VERSION "f32"

NS_ :

BS_:

BU_: C70 VC MCU BMS CHG DASH PBX

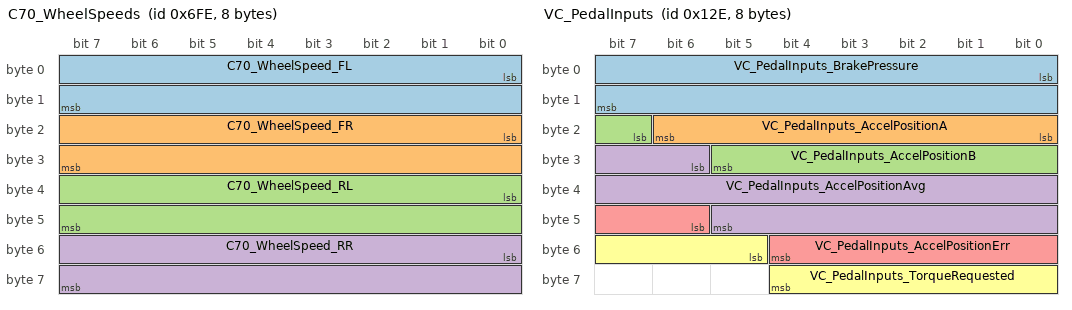
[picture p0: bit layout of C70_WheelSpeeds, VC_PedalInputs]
BO_ 1790 C70_WheelSpeeds: 8 C70
 SG_ C70_WheelSpeed_FL : 0|16@1- (1,0) [0|65536] ""  C70
 SG_ C70_WheelSpeed_FR : 16|16@1- (1,0) [0|65536] ""  C70
 SG_ C70_WheelSpeed_RL : 32|16@1- (1,0) [0|65536] ""  C70
 SG_ C70_WheelSpeed_RR : 48|16@1- (1,0) [0|65536] ""  C70

BO_ 1791 C70_BrakePressures: 8 C70
 SG_ C70_BrakePressureFront : 0|16@1- (0.2,1250) [0|2500] "psi" Vector__XXX
 SG_ C70_BrakePressureRear : 16|16@1- (0.2,1250) [0|2500] "psi" Vector__XXX

BO_ 301 VC_Status: 8 VC
 SG_ VC_Status_VehicleState : 0|4@1+ (1,0) [0|15] ""  DASH
 SG_ VC_Status_MC_State : 4|4@1+ (1,0) [0|15] ""  DASH

BO_ 302 VC_PedalInputs: 8 VC
 SG_ VC_PedalInputs_BrakePressure : 0|16@1+ (0.1,0) [0|3000] "psi" Vector__XXX
 SG_ VC_PedalInputs_AccelPositionA : 16|7@1+ (1,0) [0|100] "%" Vector__XXX
 SG_ VC_PedalInputs_AccelPositionB : 23|7@1+ (1,0) [0|100] "%" Vector__XXX
 SG_ VC_PedalInputs_AccelPositionAvg : 30|16@1+ (0.1,0) [0|100] "%" Vector__XXX
 SG_ VC_PedalInputs_AccelPositionErr : 46|7@1+ (1,0) [0|100] "%" Vector__XXX
 SG_ VC_PedalInputs_TorqueRequested : 53|8@1+ (1,0) [0|254] "Nm" Vector__XXX

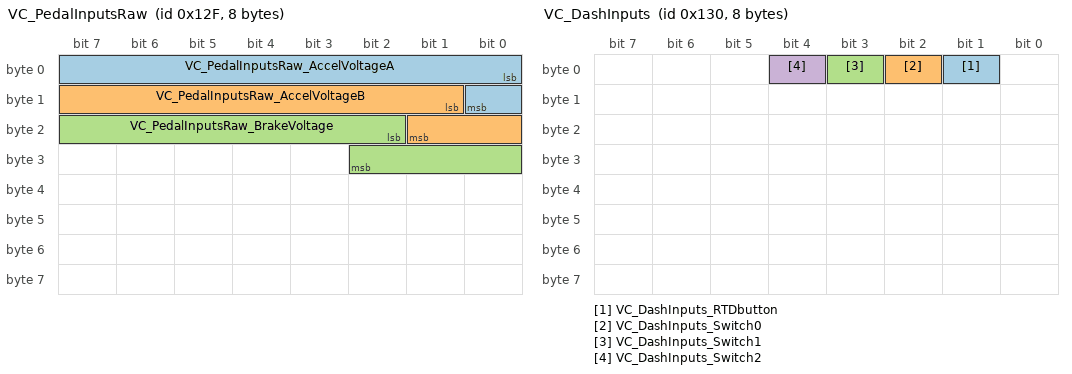
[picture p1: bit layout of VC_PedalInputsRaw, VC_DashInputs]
BO_ 303 VC_PedalInputsRaw: 8 VC
 SG_ VC_PedalInputsRaw_AccelVoltageA : 0|9@1+ (0.01,0) [0|5] "V" Vector__XXX
 SG_ VC_PedalInputsRaw_AccelVoltageB : 9|9@1+ (0.01,0) [0|5] "V" Vector__XXX
 SG_ VC_PedalInputsRaw_BrakeVoltage : 18|9@1+ (0.01,0) [0|5] "V" Vector__XXX

BO_ 304 VC_DashInputs: 8 VC
 SG_ VC_DashInputs_RTDbutton : 1|1@1+ (1,0) [0|1] "" Vector__XXX
 SG_ VC_DashInputs_Switch0 : 2|1@1+ (1,0) [0|1] "" Vector__XXX
 SG_ VC_DashInputs_Switch1 : 3|1@1+ (1,0) [0|1] "" Vector__XXX
 SG_ VC_DashInputs_Switch2 : 4|1@1+ (1,0) [0|1] "" Vector__XXX

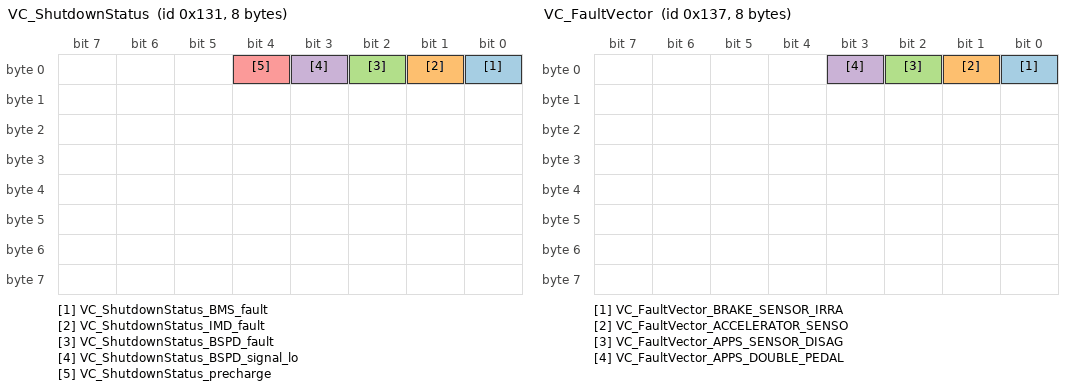
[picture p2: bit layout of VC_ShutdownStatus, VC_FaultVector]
BO_ 305 VC_ShutdownStatus: 8 VC
 SG_ VC_ShutdownStatus_BMS_fault : 0|1@1+ (1,0) [0|1] "" Vector__XXX
 SG_ VC_ShutdownStatus_IMD_fault : 1|1@1+ (1,0) [0|1] "" Vector__XXX
 SG_ VC_ShutdownStatus_BSPD_fault : 2|1@1+ (1,0) [0|1] "" Vector__XXX
 SG_ VC_ShutdownStatus_BSPD_signal_lo : 3|1@1+ (1,0) [0|1] "" Vector__XXX
 SG_ VC_ShutdownStatus_precharge : 4|1@1+ (1,0) [0|1] "" Vector__XXX

BO_ 311 VC_FaultVector: 8 VC
 SG_ VC_FaultVector_BRAKE_SENSOR_IRRA : 0|1@1+ (1,0) [0|1] ""  DASH
 SG_ VC_FaultVector_ACCELERATOR_SENSO : 1|1@1+ (1,0) [0|1] ""  DASH
 SG_ VC_FaultVector_APPS_SENSOR_DISAG : 2|1@1+ (1,0) [0|1] ""  DASH
 SG_ VC_FaultVector_APPS_DOUBLE_PEDAL : 3|1@1+ (1,0) [0|1] ""  DASH

BO_ 315 VC_HardFaultIndicator: 8 VC
 SG_ VC_HardFaultIndicator_task : 0|4@1+ (1,0) [0|15] ""  DASH

BO_ 316 VC_RTDSRequest: 8 VC
 SG_ VC_RequestRTDS : 0|1@1+ (1,0) [0|1] "" Vector__XXX

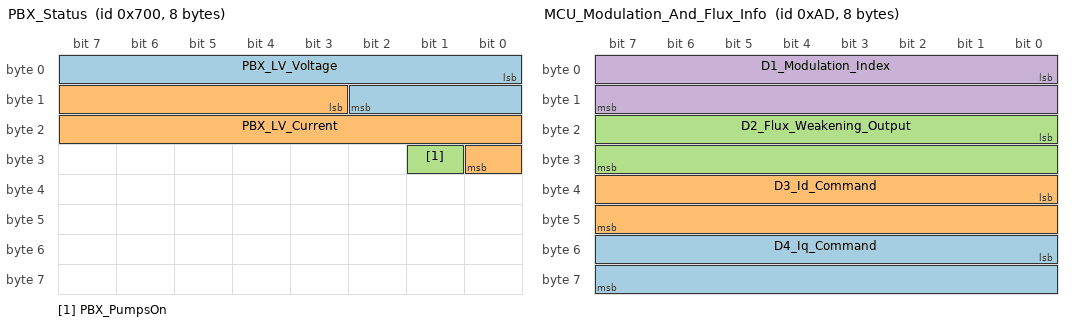
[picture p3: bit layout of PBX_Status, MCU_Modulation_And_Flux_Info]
BO_ 1792 PBX_Status: 8 PBX
 SG_ PBX_LV_Voltage : 0|11@1+ (0.01,0) [0|20] "V" Vector__XXX
 SG_ PBX_LV_Current : 11|14@1+ (0.01,0) [0|100] "A" Vector__XXX
 SG_ PBX_PumpsOn : 25|1@1+ (1,0) [0|1] ""  VC

BO_ 173 MCU_Modulation_And_Flux_Info: 8 MCU
 SG_ D4_Iq_Command : 48|16@1- (0.1,0) [-3276.8|3276.7] "A" Vector__XXX
 SG_ D3_Id_Command : 32|16@1- (0.1,0) [-3276.8|3276.7] "A" Vector__XXX
 SG_ D2_Flux_Weakening_Output : 16|16@1- (0.1,0) [-3276.8|3276.7] "A" Vector__XXX
 SG_ D1_Modulation_Index : 0|16@1- (0.0001,0) [-3.2768|3.2767] "" Vector__XXX

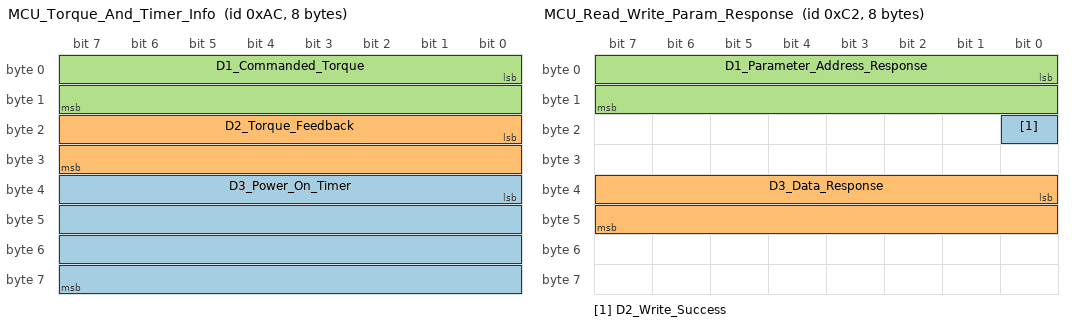
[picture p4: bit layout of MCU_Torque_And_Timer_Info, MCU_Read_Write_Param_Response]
BO_ 172 MCU_Torque_And_Timer_Info: 8 MCU
 SG_ D3_Power_On_Timer : 32|32@1+ (0.003,0) [0|12884800] "Sec" Vector__XXX
 SG_ D2_Torque_Feedback : 16|16@1- (0.1,0) [-3276.8|3276.7] "Nm" Vector__XXX
 SG_ D1_Commanded_Torque : 0|16@1- (0.1,0) [-3276.8|3276.7] "Nm" Vector__XXX

BO_ 194 MCU_Read_Write_Param_Response: 8 MCU
 SG_ D2_Write_Success : 16|1@1+ (1,0) [0|1] "" Vector__XXX
 SG_ D3_Data_Response : 32|16@1- (1,0) [-32768|32767] "" Vector__XXX
 SG_ D1_Parameter_Address_Response : 0|16@1+ (1,0) [0|65535] "" Vector__XXX

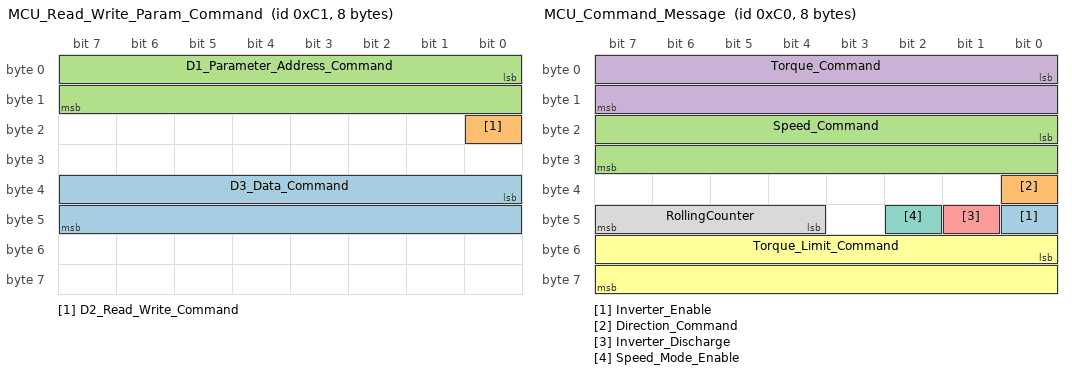
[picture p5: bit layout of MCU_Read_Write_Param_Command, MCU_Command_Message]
BO_ 193 MCU_Read_Write_Param_Command: 8 VC
 SG_ D3_Data_Command : 32|16@1- (1,0) [-32768|32767] ""  MCU
 SG_ D2_Read_Write_Command : 16|1@1+ (1,0) [0|1] ""  MCU
 SG_ D1_Parameter_Address_Command : 0|16@1+ (1,0) [0|65535] ""  MCU

BO_ 192 MCU_Command_Message: 8 VC
 SG_ Inverter_Enable : 40|1@1+ (1,0) [0|1] "Bit"  MCU
 SG_ Direction_Command : 32|1@1+ (1,0) [0|1] "Bit"  MCU
 SG_ Speed_Command : 16|16@1- (1,0) [-32768|32767] "rpm"  MCU
 SG_ Torque_Command : 0|16@1- (0.1,0) [-3276.8|3276.7] "Nm"  MCU
 SG_ Inverter_Discharge : 41|1@1+ (1,0) [0|1] "Bit"  MCU
 SG_ Torque_Limit_Command : 48|16@1- (0.1,0) [-3276.8|3276.7] "Nm"  MCU
 SG_ Speed_Mode_Enable : 42|1@1+ (1,0) [0|1] "Bit"  MCU
 SG_ RollingCounter : 44|4@1+ (1,0) [0|15] "Bits"  MCU

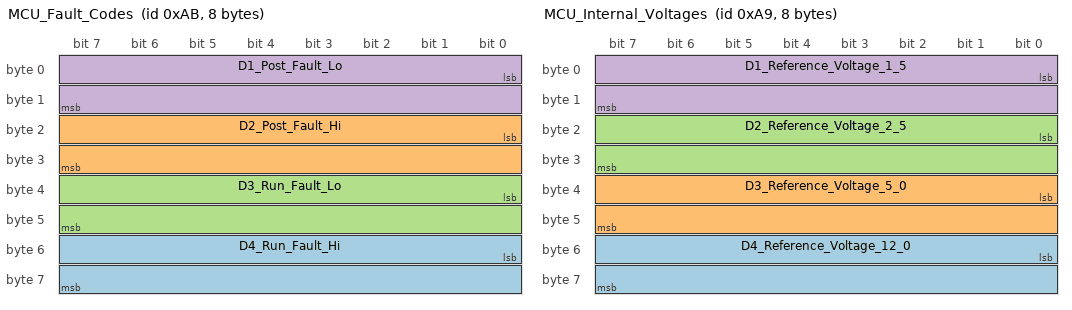
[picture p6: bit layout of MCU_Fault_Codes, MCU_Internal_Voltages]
BO_ 171 MCU_Fault_Codes: 8 MCU
 SG_ D4_Run_Fault_Hi : 48|16@1+ (1,0) [0|65535] "" Vector__XXX
 SG_ D2_Post_Fault_Hi : 16|16@1+ (1,0) [0|65535] "" Vector__XXX
 SG_ D3_Run_Fault_Lo : 32|16@1+ (1,0) [0|65535] "" Vector__XXX
 SG_ D1_Post_Fault_Lo : 0|16@1+ (1,0) [0|65535] "" Vector__XXX

BO_ 170 MCU_Internal_States: 8 MCU
 SG_ D7_Direction_Command : 56|1@1+ (1,0) [0|1] "" Vector__XXX
 SG_ D6_Inverter_Enable_State : 48|1@1+ (1,0) [0|1] "" Vector__XXX
 SG_ D3_Relay_3_Status : 26|1@1+ (1,0) [0|1] "" Vector__XXX
 SG_ D3_Relay_4_Status : 27|1@1+ (1,0) [0|1] "" Vector__XXX
 SG_ D3_Relay_2_Status : 25|1@1+ (1,0) [0|1] "" Vector__XXX
 SG_ D4_Inverter_Run_Mode : 32|1@1+ (1,0) [0|1] "" Vector__XXX
 SG_ D5_Inverter_Command_Mode : 40|1@1+ (1,0) [0|1] "" Vector__XXX
 SG_ D3_Relay_1_Status : 24|1@1+ (1,0) [0|1] "" Vector__XXX
 SG_ D2_Inverter_State : 16|8@1+ (1,0) [0|255] "" Vector__XXX
 SG_ D1_VSM_State : 0|8@1+ (1,0) [0|15] "" Vector__XXX
 SG_ D6_Inverter_Enable_Lockout : 55|1@1+ (1,0) [0|1] "" Vector__XXX
 SG_ D4_Inverter_Discharge_State : 37|3@1+ (1,0) [0|7] "" Vector__XXX
 SG_ D3_Relay_5_Status : 28|1@1+ (1,0) [0|1] "" Vector__XXX
 SG_ D3_Relay_6_Status : 29|1@1+ (1,0) [0|1] "" Vector__XXX
 SG_ D7_BMS_Active : 57|1@1+ (1,0) [0|1] "" Vector__XXX
 SG_ D7_BMS_Torque_Limiting : 58|1@1+ (1,0) [0|1] "" Vector__XXX
 SG_ D7_Max_Speed_Limiting : 59|1@1+ (1,0) [0|1] "" Vector__XXX
 SG_ D7_Low_Speed_Limiting : 61|1@1+ (1,0) [0|1] "" Vector__XXX
 SG_ D5_Rolling_Counter : 44|4@1+ (1,0) [0|15] "" Vector__XXX
 SG_ D1_PWM_Frequency : 8|8@1+ (1,0) [0|255] "kHz" Vector__XXX
 SG_ D6_Start_Mode_Active : 54|1@1+ (1,0) [0|1] "" Vector__XXX

BO_ 169 MCU_Internal_Voltages: 8 MCU
 SG_ D4_Reference_Voltage_12_0 : 48|16@1- (0.01,0) [-327.68|327.67] "V" Vector__XXX
 SG_ D3_Reference_Voltage_5_0 : 32|16@1- (0.01,0) [-327.68|327.67] "V" Vector__XXX
 SG_ D2_Reference_Voltage_2_5 : 16|16@1- (0.01,0) [-327.68|327.67] "V" Vector__XXX
 SG_ D1_Reference_Voltage_1_5 : 0|16@1- (0.01,0) [-327.68|327.67] "V" Vector__XXX

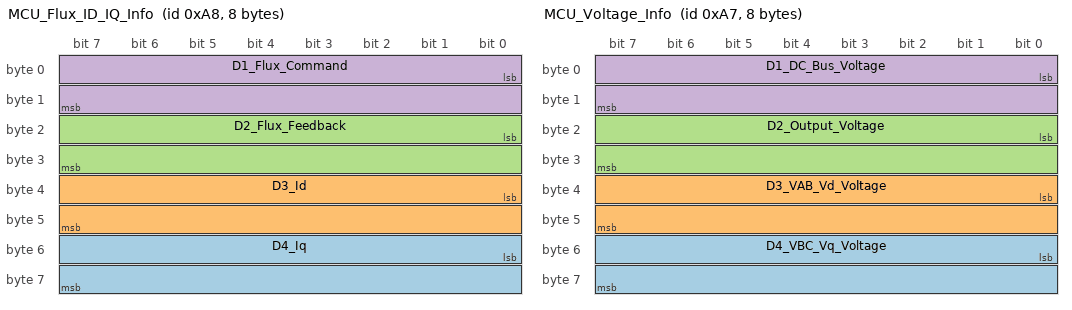
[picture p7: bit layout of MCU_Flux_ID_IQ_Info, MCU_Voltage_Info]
BO_ 168 MCU_Flux_ID_IQ_Info: 8 MCU
 SG_ D4_Iq : 48|16@1- (0.1,0) [-3276.8|3276.7] "A" Vector__XXX
 SG_ D3_Id : 32|16@1- (0.1,0) [-3276.8|3276.7] "A" Vector__XXX
 SG_ D2_Flux_Feedback : 16|16@1- (0.001,0) [-32.768|32.767] "Wb" Vector__XXX
 SG_ D1_Flux_Command : 0|16@1- (0.001,0) [-32.768|32.767] "Wb" Vector__XXX

BO_ 167 MCU_Voltage_Info: 8 MCU
 SG_ D4_VBC_Vq_Voltage : 48|16@1- (0.1,0) [-3276.8|3276.7] "V" Vector__XXX
 SG_ D3_VAB_Vd_Voltage : 32|16@1- (0.1,0) [-3276.8|3276.7] "V" Vector__XXX
 SG_ D2_Output_Voltage : 16|16@1- (0.1,0) [-3276.8|3276.7] "V" Vector__XXX
 SG_ D1_DC_Bus_Voltage : 0|16@1- (0.1,0) [-3276.8|3276.7] "V" Vector__XXX

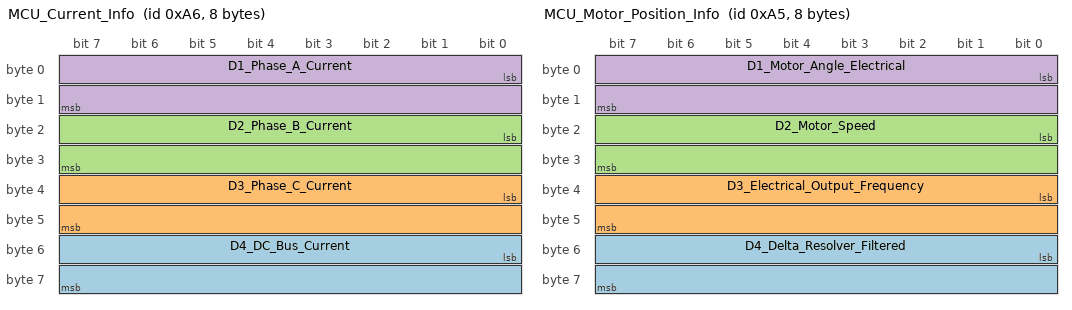
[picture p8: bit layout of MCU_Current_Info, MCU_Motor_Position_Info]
BO_ 166 MCU_Current_Info: 8 MCU
 SG_ D4_DC_Bus_Current : 48|16@1- (0.1,0) [-3276.8|3276.7] "A" Vector__XXX
 SG_ D3_Phase_C_Current : 32|16@1- (0.1,0) [-3276.8|3276.7] "A" Vector__XXX
 SG_ D2_Phase_B_Current : 16|16@1- (0.1,0) [-3276.8|3276.7] "A" Vector__XXX
 SG_ D1_Phase_A_Current : 0|16@1- (0.1,0) [-3276.8|3276.7] "A" Vector__XXX

BO_ 165 MCU_Motor_Position_Info: 8 MCU
 SG_ D4_Delta_Resolver_Filtered : 48|16@1- (0.1,0) [-3276.8|3276.7] "deg" Vector__XXX
 SG_ D3_Electrical_Output_Frequency : 32|16@1- (0.1,0) [-3276.8|3276.7] "hz" Vector__XXX
 SG_ D2_Motor_Speed : 16|16@1- (1,0) [-32768|32767] "rpm"  DASH
 SG_ D1_Motor_Angle_Electrical : 0|16@1+ (0.1,0) [0|6553.5] "deg" Vector__XXX

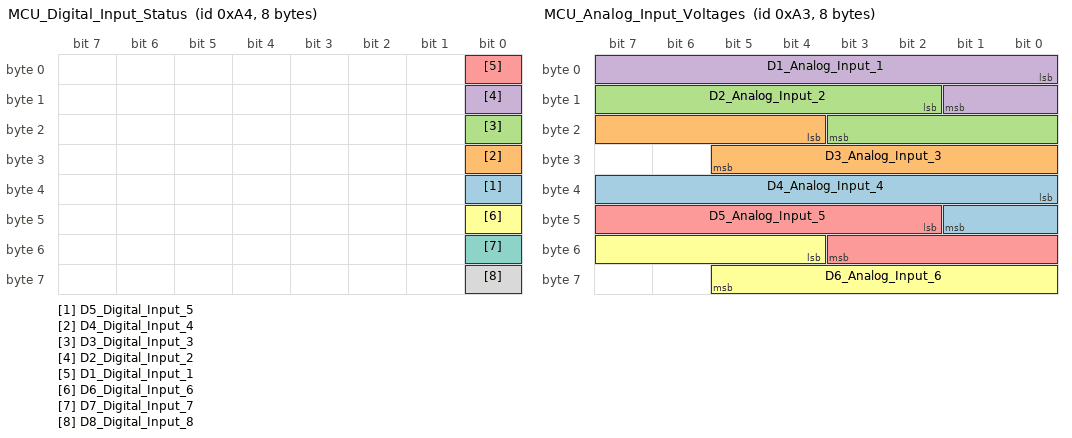
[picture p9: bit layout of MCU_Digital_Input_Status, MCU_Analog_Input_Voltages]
BO_ 164 MCU_Digital_Input_Status: 8 MCU
 SG_ D5_Digital_Input_5 : 32|1@1+ (1,0) [0|1] "boolean" Vector__XXX
 SG_ D4_Digital_Input_4 : 24|1@1+ (1,0) [0|1] "boolean" Vector__XXX
 SG_ D3_Digital_Input_3 : 16|1@1+ (1,0) [0|1] "boolean" Vector__XXX
 SG_ D2_Digital_Input_2 : 8|1@1+ (1,0) [0|1] "boolean" Vector__XXX
 SG_ D1_Digital_Input_1 : 0|1@1+ (1,0) [0|1] "boolean" Vector__XXX
 SG_ D6_Digital_Input_6 : 40|1@1+ (1,0) [0|1] "boolean" Vector__XXX
 SG_ D7_Digital_Input_7 : 48|1@1+ (1,0) [0|1] "boolean" Vector__XXX
 SG_ D8_Digital_Input_8 : 56|1@1+ (1,0) [0|1] "boolean" Vector__XXX

BO_ 163 MCU_Analog_Input_Voltages: 8 MCU
 SG_ D4_Analog_Input_4 : 32|10@1+ (0.01,0) [0|10.23] "V" Vector__XXX
 SG_ D3_Analog_Input_3 : 20|10@1+ (0.01,0) [0|10.23] "V" Vector__XXX
 SG_ D2_Analog_Input_2 : 10|10@1+ (0.01,0) [0|10.23] "V" Vector__XXX
 SG_ D1_Analog_Input_1 : 0|10@1+ (0.01,0) [0|10.23] "V" Vector__XXX
 SG_ D5_Analog_Input_5 : 42|10@1+ (0.01,0) [0|10.23] "V" Vector__XXX
 SG_ D6_Analog_Input_6 : 52|10@1+ (0.01,0) [0|10.23] "V" Vector__XXX

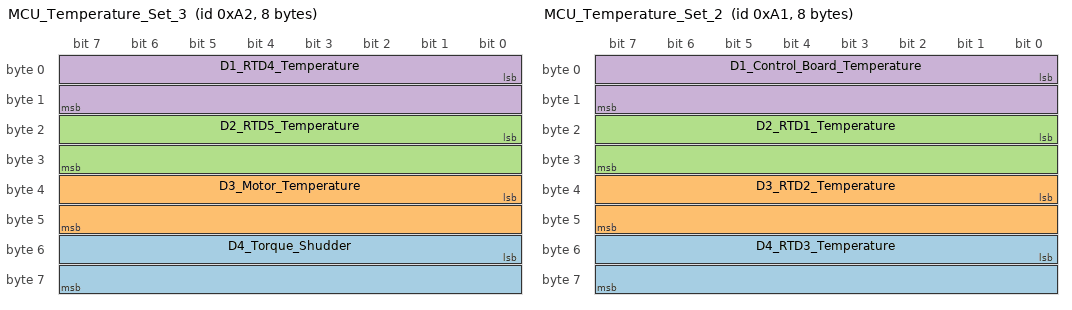
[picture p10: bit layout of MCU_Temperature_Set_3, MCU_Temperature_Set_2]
BO_ 162 MCU_Temperature_Set_3: 8 MCU
 SG_ D4_Torque_Shudder : 48|16@1- (0.1,0) [-3276.8|3276.7] "Nm" Vector__XXX
 SG_ D3_Motor_Temperature : 32|16@1- (0.1,0) [-3276.8|3276.7] "degC" Vector__XXX
 SG_ D2_RTD5_Temperature : 16|16@1- (0.1,0) [-3276.8|3276.7] "degC" Vector__XXX
 SG_ D1_RTD4_Temperature : 0|16@1- (0.1,0) [-3276.8|3276.7] "degC" Vector__XXX

BO_ 161 MCU_Temperature_Set_2: 8 MCU
 SG_ D4_RTD3_Temperature : 48|16@1- (0.1,0) [-3276.8|3276.7] "degC" Vector__XXX
 SG_ D3_RTD2_Temperature : 32|16@1- (0.1,0) [-3276.8|3276.7] "degC" Vector__XXX
 SG_ D2_RTD1_Temperature : 16|16@1- (0.1,0) [-3276.8|3276.7] "degC" Vector__XXX
 SG_ D1_Control_Board_Temperature : 0|16@1- (0.1,0) [-3276.8|3276.7] "degC" Vector__XXX

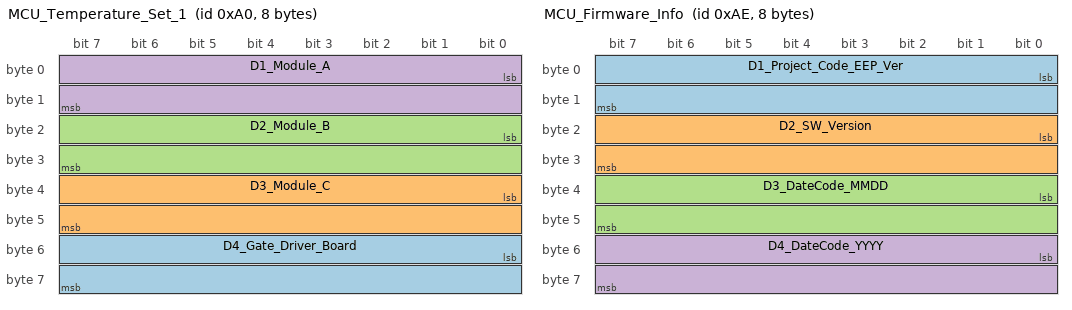
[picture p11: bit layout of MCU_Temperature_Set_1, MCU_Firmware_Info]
BO_ 160 MCU_Temperature_Set_1: 8 MCU
 SG_ D4_Gate_Driver_Board : 48|16@1- (0.1,0) [-3276.8|3276.7] "degC" Vector__XXX
 SG_ D3_Module_C : 32|16@1- (0.1,0) [-3276.8|3276.7] "degC" Vector__XXX
 SG_ D2_Module_B : 16|16@1- (0.1,0) [-3276.8|3276.7] "degC" Vector__XXX
 SG_ D1_Module_A : 0|16@1- (0.1,0) [-3276.8|3276.7] "degC" Vector__XXX

BO_ 174 MCU_Firmware_Info: 8 MCU
 SG_ D1_Project_Code_EEP_Ver : 0|16@1+ (1,0) [0|65535] "" Vector__XXX
 SG_ D2_SW_Version : 16|16@1+ (1,0) [0|65535] "" Vector__XXX
 SG_ D3_DateCode_MMDD : 32|16@1+ (1,0) [0|65535] "" Vector__XXX
 SG_ D4_DateCode_YYYY : 48|16@1+ (1,0) [0|65535] "" Vector__XXX

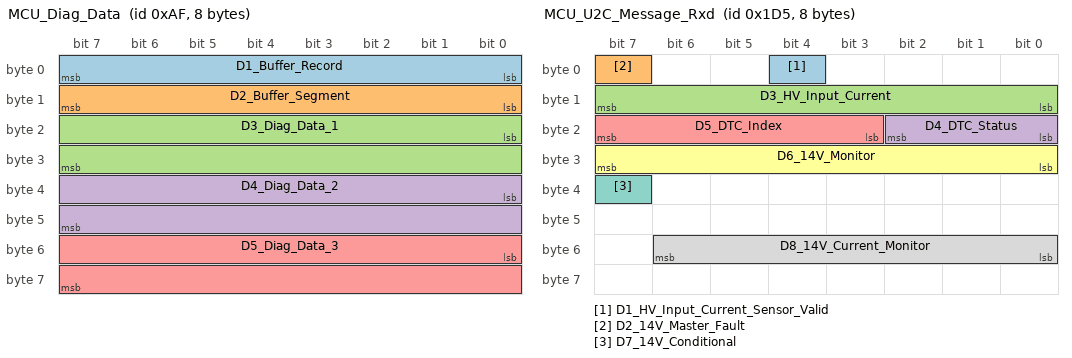
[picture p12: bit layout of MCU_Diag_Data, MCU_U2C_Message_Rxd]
BO_ 175 MCU_Diag_Data: 8 MCU
 SG_ D1_Buffer_Record : 0|8@1+ (1,0) [0|255] "" Vector__XXX
 SG_ D2_Buffer_Segment : 8|8@1+ (1,0) [0|5] "" Vector__XXX
 SG_ D3_Diag_Data_1 : 16|16@1- (1,0) [-32768|32767] "" Vector__XXX
 SG_ D4_Diag_Data_2 : 32|16@1- (1,0) [-32768|32767] "" Vector__XXX
 SG_ D5_Diag_Data_3 : 48|16@1- (1,0) [-32768|32767] "" Vector__XXX

BO_ 471 MCU_U2C_Command_Txd: 8 MCU
 SG_ D1_ID_Byte : 0|8@1+ (1,0) [0|255] "" Vector__XXX
 SG_ D2_Setpoint_Calc : 8|8@1+ (1,0) [0|255] "" Vector__XXX

BO_ 469 MCU_U2C_Message_Rxd: 8 MCU
 SG_ D1_HV_Input_Current_Sensor_Valid : 4|1@1+ (1,0) [0|1] "" Vector__XXX
 SG_ D2_14V_Master_Fault : 7|1@1+ (1,0) [0|1] "" Vector__XXX
 SG_ D3_HV_Input_Current : 8|8@1+ (1,0) [0|255] "" Vector__XXX
 SG_ D4_DTC_Status : 16|3@1+ (1,0) [0|7] "" Vector__XXX
 SG_ D5_DTC_Index : 19|5@1+ (1,0) [0|31] "" Vector__XXX
 SG_ D6_14V_Monitor : 24|8@1+ (1,0) [0|255] "" Vector__XXX
 SG_ D7_14V_Conditional : 39|1@1+ (1,0) [0|1] "" Vector__XXX
 SG_ D8_14V_Current_Monitor : 48|7@1+ (1,0) [0|127] "" Vector__XXX

BO_ 514 BMS_Current_Limit: 8 BMS
 SG_ D1_Max_Discharge_Current : 0|16@1+ (1,0) [0|1000] "A" Vector__XXX
 SG_ D2_Max_Charge_Current : 16|16@1+ (1,0) [0|1000] "A" Vector__XXX

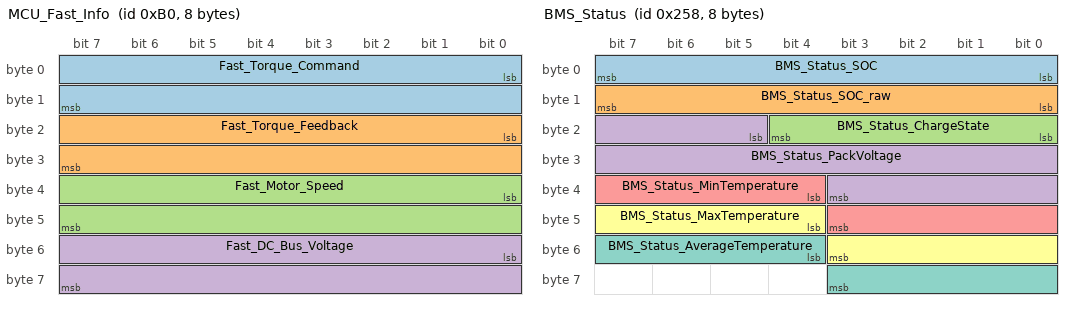
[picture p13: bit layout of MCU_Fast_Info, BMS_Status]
BO_ 176 MCU_Fast_Info: 8 MCU
 SG_ Fast_Torque_Command : 0|16@1- (0.1,0) [-3276.8|3276.7] "Nm" Vector__XXX
 SG_ Fast_Torque_Feedback : 16|16@1- (0.1,0) [-3276.8|3276.7] "Nm" Vector__XXX
 SG_ Fast_Motor_Speed : 32|16@1- (1,0) [-32768|32767] "rpm" Vector__XXX
 SG_ Fast_DC_Bus_Voltage : 48|16@1- (0.1,0) [-3276.8|3276.7] "V" Vector__XXX

BO_ 600 BMS_Status: 8 BMS
 SG_ BMS_Status_SOC : 0|8@1+ (1,0) [0|100] "%"  DASH
 SG_ BMS_Status_SOC_raw : 8|8@1+ (1,0) [0|100] "%" Vector__XXX
 SG_ BMS_Status_ChargeState : 16|5@1+ (1,0) [0|4] "" Vector__XXX
 SG_ BMS_Status_PackVoltage : 21|15@1+ (0.1,0) [0|400] "V"  DASH
 SG_ BMS_Status_MinTemperature : 36|8@1- (1,0) [-128|127] "C" Vector__XXX
 SG_ BMS_Status_MaxTemperature : 44|8@1- (1,0) [-128|127] "C" Vector__XXX
 SG_ BMS_Status_AverageTemperature : 52|8@1- (1,0) [-128|127] "C" Vector__XXX

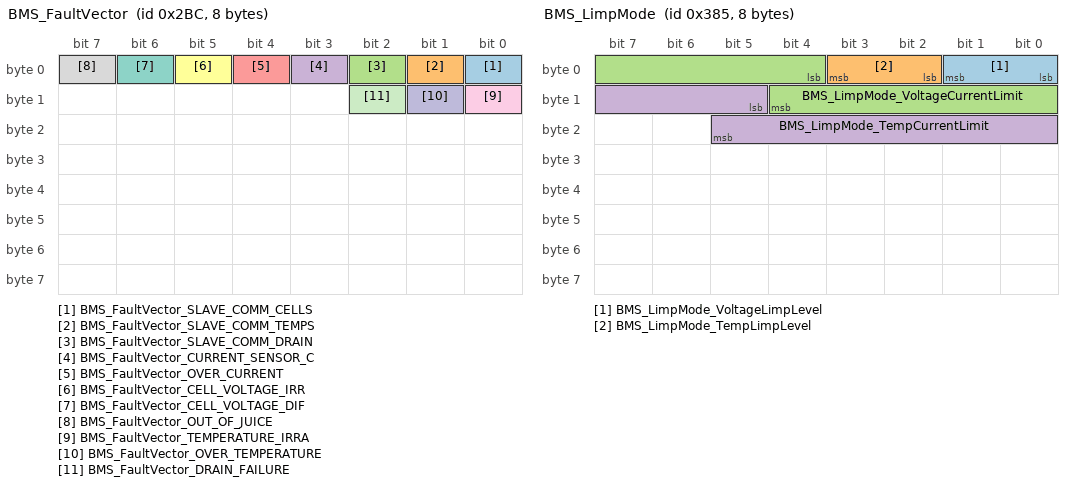
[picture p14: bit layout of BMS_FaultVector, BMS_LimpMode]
BO_ 700 BMS_FaultVector: 8 BMS
 SG_ BMS_FaultVector_SLAVE_COMM_CELLS : 0|1@1+ (1,0) [0|1] ""  DASH
 SG_ BMS_FaultVector_SLAVE_COMM_TEMPS : 1|1@1+ (1,0) [0|1] ""  DASH
 SG_ BMS_FaultVector_SLAVE_COMM_DRAIN : 2|1@1+ (1,0) [0|1] ""  DASH
 SG_ BMS_FaultVector_CURRENT_SENSOR_C : 3|1@1+ (1,0) [0|1] ""  DASH
 SG_ BMS_FaultVector_OVER_CURRENT : 4|1@1+ (1,0) [0|1] ""  DASH
 SG_ BMS_FaultVector_CELL_VOLTAGE_IRR : 5|1@1+ (1,0) [0|1] ""  DASH
 SG_ BMS_FaultVector_CELL_VOLTAGE_DIF : 6|1@1+ (1,0) [0|1] ""  DASH
 SG_ BMS_FaultVector_OUT_OF_JUICE : 7|1@1+ (1,0) [0|1] ""  DASH
 SG_ BMS_FaultVector_TEMPERATURE_IRRA : 8|1@1+ (1,0) [0|1] ""  DASH
 SG_ BMS_FaultVector_OVER_TEMPERATURE : 9|1@1+ (1,0) [0|1] ""  DASH
 SG_ BMS_FaultVector_DRAIN_FAILURE : 10|1@1+ (1,0) [0|1] ""  DASH

BO_ 701 BMS_FaultAlert: 8 BMS
 SG_ BMS_FaultAlert_code M : 0|6@1+ (1,0) [0|63] "" Vector__XXX
 SG_ BMS_FaultAlert_cell_comm_slave_b m0 : 6|8@1+ (1,0) [0|255] "" Vector__XXX
 SG_ BMS_FaultAlert_temp_comm_slave_b m1 : 6|8@1+ (1,0) [0|255] "" Vector__XXX
 SG_ BMS_FaultAlert_drain_comm_slave_ m2 : 6|8@1+ (1,0) [0|255] "" Vector__XXX
 SG_ BMS_FaultAlert_adc_error_code m3 : 6|8@1+ (1,0) [0|255] "" Vector__XXX
 SG_ BMS_FaultAlert_current m4 : 6|32@1+ (0.001,0) [0|2000] "A" Vector__XXX
 SG_ BMS_FaultAlert_irrational_voltag m5 : 6|9@1+ (0.01,0) [0|5.12] "V" Vector__XXX
 SG_ BMS_FaultAlert_voltage_diff m6 : 6|9@1+ (0.01,0) [0|5.12] "V" Vector__XXX
 SG_ BMS_FaultAlert_lowest_cell_volta m7 : 6|9@1+ (0.01,0) [0|5.12] "V" Vector__XXX
 SG_ BMS_FaultAlert_irrational_temper m8 : 6|16@1+ (0.01,0) [-327.68|327.67] "V" Vector__XXX
 SG_ BMS_FaultAlert_over_temperature m9 : 6|16@1+ (0.01,0) [-327.68|327.67] "V" Vector__XXX
 SG_ BMS_FaultAlert_failed_drain_cell m10 : 6|8@1+ (1,0) [0|255] "" Vector__XXX

BO_ 702 BMS_Voltages: 8 BMS
 SG_ BMS_Voltages_mux M : 0|8@1+ (1,0) [0|255] ""  DASH
 SG_ BMS_Voltages_Cell0 m0 : 8|9@1+ (0.01,0) [0|5.12] "V"  DASH
 SG_ BMS_Voltages_Cell1 m0 : 17|9@1+ (0.01,0) [0|5.12] "V"  DASH
 SG_ BMS_Voltages_Cell2 m0 : 26|9@1+ (0.01,0) [0|5.12] "V"  DASH
 SG_ BMS_Voltages_Cell3 m0 : 35|9@1+ (0.01,0) [0|5.12] "V"  DASH
 SG_ BMS_Voltages_Cell4 m0 : 44|9@1+ (0.01,0) [0|5.12] "V"  DASH
 SG_ BMS_Voltages_Cell5 m0 : 53|9@1+ (0.01,0) [0|5.12] "V"  DASH
 SG_ BMS_Voltages_Cell6 m1 : 8|9@1+ (0.01,0) [0|5.12] "V"  DASH
 SG_ BMS_Voltages_Cell7 m1 : 17|9@1+ (0.01,0) [0|5.12] "V"  DASH
 SG_ BMS_Voltages_Cell8 m1 : 26|9@1+ (0.01,0) [0|5.12] "V"  DASH
 SG_ BMS_Voltages_Cell9 m1 : 35|9@1+ (0.01,0) [0|5.12] "V"  DASH
 SG_ BMS_Voltages_Cell10 m1 : 44|9@1+ (0.01,0) [0|5.12] "V"  DASH
 SG_ BMS_Voltages_Cell11 m1 : 53|9@1+ (0.01,0) [0|5.12] "V"  DASH
 SG_ BMS_Voltages_Cell12 m2 : 8|9@1+ (0.01,0) [0|5.12] "V"  DASH
 SG_ BMS_Voltages_Cell13 m2 : 17|9@1+ (0.01,0) [0|5.12] "V"  DASH
 SG_ BMS_Voltages_Cell14 m2 : 26|9@1+ (0.01,0) [0|5.12] "V"  DASH
 SG_ BMS_Voltages_Cell15 m2 : 35|9@1+ (0.01,0) [0|5.12] "V"  DASH
 SG_ BMS_Voltages_Cell16 m2 : 44|9@1+ (0.01,0) [0|5.12] "V"  DASH
 SG_ BMS_Voltages_Cell17 m2 : 53|9@1+ (0.01,0) [0|5.12] "V"  DASH
 SG_ BMS_Voltages_Cell18 m3 : 8|9@1+ (0.01,0) [0|5.12] "V"  DASH
 SG_ BMS_Voltages_Cell19 m3 : 17|9@1+ (0.01,0) [0|5.12] "V"  DASH
 SG_ BMS_Voltages_Cell20 m3 : 26|9@1+ (0.01,0) [0|5.12] "V"  DASH
 SG_ BMS_Voltages_Cell21 m3 : 35|9@1+ (0.01,0) [0|5.12] "V"  DASH
 SG_ BMS_Voltages_Cell22 m3 : 44|9@1+ (0.01,0) [0|5.12] "V"  DASH
 SG_ BMS_Voltages_Cell23 m3 : 53|9@1+ (0.01,0) [0|5.12] "V"  DASH
 SG_ BMS_Voltages_Cell24 m4 : 8|9@1+ (0.01,0) [0|5.12] "V"  DASH
 SG_ BMS_Voltages_Cell25 m4 : 17|9@1+ (0.01,0) [0|5.12] "V"  DASH
 SG_ BMS_Voltages_Cell26 m4 : 26|9@1+ (0.01,0) [0|5.12] "V"  DASH
 SG_ BMS_Voltages_Cell27 m4 : 35|9@1+ (0.01,0) [0|5.12] "V"  DASH
 SG_ BMS_Voltages_Cell28 m4 : 44|9@1+ (0.01,0) [0|5.12] "V"  DASH
 SG_ BMS_Voltages_Cell29 m4 : 53|9@1+ (0.01,0) [0|5.12] "V"  DASH
 SG_ BMS_Voltages_Cell30 m5 : 8|9@1+ (0.01,0) [0|5.12] "V"  DASH
 SG_ BMS_Voltages_Cell31 m5 : 17|9@1+ (0.01,0) [0|5.12] "V"  DASH
 SG_ BMS_Voltages_Cell32 m5 : 26|9@1+ (0.01,0) [0|5.12] "V"  DASH
 SG_ BMS_Voltages_Cell33 m5 : 35|9@1+ (0.01,0) [0|5.12] "V"  DASH
 SG_ BMS_Voltages_Cell34 m5 : 44|9@1+ (0.01,0) [0|5.12] "V"  DASH
 SG_ BMS_Voltages_Cell35 m5 : 53|9@1+ (0.01,0) [0|5.12] "V"  DASH
 SG_ BMS_Voltages_Cell36 m6 : 8|9@1+ (0.01,0) [0|5.12] "V"  DASH
 SG_ BMS_Voltages_Cell37 m6 : 17|9@1+ (0.01,0) [0|5.12] "V"  DASH
 SG_ BMS_Voltages_Cell38 m6 : 26|9@1+ (0.01,0) [0|5.12] "V"  DASH
 SG_ BMS_Voltages_Cell39 m6 : 35|9@1+ (0.01,0) [0|5.12] "V"  DASH
 SG_ BMS_Voltages_Cell40 m6 : 44|9@1+ (0.01,0) [0|5.12] "V"  DASH
 SG_ BMS_Voltages_Cell41 m6 : 53|9@1+ (0.01,0) [0|5.12] "V"  DASH
 SG_ BMS_Voltages_Cell42 m7 : 8|9@1+ (0.01,0) [0|5.12] "V"  DASH
 SG_ BMS_Voltages_Cell43 m7 : 17|9@1+ (0.01,0) [0|5.12] "V"  DASH
 SG_ BMS_Voltages_Cell44 m7 : 26|9@1+ (0.01,0) [0|5.12] "V"  DASH
 SG_ BMS_Voltages_Cell45 m7 : 35|9@1+ (0.01,0) [0|5.12] "V"  DASH
 SG_ BMS_Voltages_Cell46 m7 : 44|9@1+ (0.01,0) [0|5.12] "V"  DASH
 SG_ BMS_Voltages_Cell47 m7 : 53|9@1+ (0.01,0) [0|5.12] "V"  DASH
 SG_ BMS_Voltages_Cell48 m8 : 8|9@1+ (0.01,0) [0|5.12] "V"  DASH
 SG_ BMS_Voltages_Cell49 m8 : 17|9@1+ (0.01,0) [0|5.12] "V"  DASH
 SG_ BMS_Voltages_Cell50 m8 : 26|9@1+ (0.01,0) [0|5.12] "V"  DASH
 SG_ BMS_Voltages_Cell51 m8 : 35|9@1+ (0.01,0) [0|5.12] "V"  DASH
 SG_ BMS_Voltages_Cell52 m8 : 44|9@1+ (0.01,0) [0|5.12] "V"  DASH
 SG_ BMS_Voltages_Cell53 m8 : 53|9@1+ (0.01,0) [0|5.12] "V"  DASH
 SG_ BMS_Voltages_Cell54 m9 : 8|9@1+ (0.01,0) [0|5.12] "V"  DASH
 SG_ BMS_Voltages_Cell55 m9 : 17|9@1+ (0.01,0) [0|5.12] "V"  DASH
 SG_ BMS_Voltages_Cell56 m9 : 26|9@1+ (0.01,0) [0|5.12] "V"  DASH
 SG_ BMS_Voltages_Cell57 m9 : 35|9@1+ (0.01,0) [0|5.12] "V"  DASH
 SG_ BMS_Voltages_Cell58 m9 : 44|9@1+ (0.01,0) [0|5.12] "V"  DASH
 SG_ BMS_Voltages_Cell59 m9 : 53|9@1+ (0.01,0) [0|5.12] "V"  DASH
 SG_ BMS_Voltages_Cell60 m10 : 8|9@1+ (0.01,0) [0|5.12] "V"  DASH
 SG_ BMS_Voltages_Cell61 m10 : 17|9@1+ (0.01,0) [0|5.12] "V"  DASH
 SG_ BMS_Voltages_Cell62 m10 : 26|9@1+ (0.01,0) [0|5.12] "V"  DASH
 SG_ BMS_Voltages_Cell63 m10 : 35|9@1+ (0.01,0) [0|5.12] "V"  DASH
 SG_ BMS_Voltages_Cell64 m10 : 44|9@1+ (0.01,0) [0|5.12] "V"  DASH
 SG_ BMS_Voltages_Cell65 m10 : 53|9@1+ (0.01,0) [0|5.12] "V"  DASH
 SG_ BMS_Voltages_Cell66 m11 : 8|9@1+ (0.01,0) [0|5.12] "V"  DASH
 SG_ BMS_Voltages_Cell67 m11 : 17|9@1+ (0.01,0) [0|5.12] "V"  DASH
 SG_ BMS_Voltages_Cell68 m11 : 26|9@1+ (0.01,0) [0|5.12] "V"  DASH
 SG_ BMS_Voltages_Cell69 m11 : 35|9@1+ (0.01,0) [0|5.12] "V"  DASH
 SG_ BMS_Voltages_Cell70 m11 : 44|9@1+ (0.01,0) [0|5.12] "V"  DASH
 SG_ BMS_Voltages_Cell71 m11 : 53|9@1+ (0.01,0) [0|5.12] "V"  DASH
 SG_ BMS_Voltages_Cell72 m12 : 8|9@1+ (0.01,0) [0|5.12] "V"  DASH
 SG_ BMS_Voltages_Cell73 m12 : 17|9@1+ (0.01,0) [0|5.12] "V"  DASH
 SG_ BMS_Voltages_Cell74 m12 : 26|9@1+ (0.01,0) [0|5.12] "V"  DASH
 SG_ BMS_Voltages_Cell75 m12 : 35|9@1+ (0.01,0) [0|5.12] "V"  DASH
 SG_ BMS_Voltages_Cell76 m12 : 44|9@1+ (0.01,0) [0|5.12] "V"  DASH
 SG_ BMS_Voltages_Cell77 m12 : 53|9@1+ (0.01,0) [0|5.12] "V"  DASH
 SG_ BMS_Voltages_Cell78 m13 : 8|9@1+ (0.01,0) [0|5.12] "V"  DASH
 SG_ BMS_Voltages_Cell79 m13 : 17|9@1+ (0.01,0) [0|5.12] "V"  DASH
 SG_ BMS_Voltages_Cell80 m13 : 26|9@1+ (0.01,0) [0|5.12] "V"  DASH
 SG_ BMS_Voltages_Cell81 m13 : 35|9@1+ (0.01,0) [0|5.12] "V"  DASH
 SG_ BMS_Voltages_Cell82 m13 : 44|9@1+ (0.01,0) [0|5.12] "V"  DASH
 SG_ BMS_Voltages_Cell83 m13 : 53|9@1+ (0.01,0) [0|5.12] "V"  DASH
 SG_ BMS_Voltages_Cell84 m14 : 8|9@1+ (0.01,0) [0|5.12] "V"  DASH
 SG_ BMS_Voltages_Cell85 m14 : 17|9@1+ (0.01,0) [0|5.12] "V"  DASH
 SG_ BMS_Voltages_Cell86 m14 : 26|9@1+ (0.01,0) [0|5.12] "V"  DASH
 SG_ BMS_Voltages_Cell87 m14 : 35|9@1+ (0.01,0) [0|5.12] "V"  DASH
 SG_ BMS_Voltages_Cell88 m14 : 44|9@1+ (0.01,0) [0|5.12] "V"  DASH
 SG_ BMS_Voltages_Cell89 m14 : 53|9@1+ (0.01,0) [0|5.12] "V"  DASH

BO_ 703 BMS_ThermistorVoltages: 8 BMS
 SG_ BMS_ThermistorVoltages_mux M : 0|3@1+ (1,0) [0|6] "" Vector__XXX
 SG_ BMS_ThermistorVoltages_tm0 m0 : 3|9@1+ (0.01,0) [0|5.12] "V" Vector__XXX
 SG_ BMS_ThermistorVoltages_tm1 m0 : 12|9@1+ (0.01,0) [0|5.12] "V" Vector__XXX
 SG_ BMS_ThermistorVoltages_tm2 m0 : 21|9@1+ (0.01,0) [0|5.12] "V" Vector__XXX
 SG_ BMS_ThermistorVoltages_tm3 m0 : 30|9@1+ (0.01,0) [0|5.12] "V" Vector__XXX
 SG_ BMS_ThermistorVoltages_tm4 m0 : 39|9@1+ (0.01,0) [0|5.12] "V" Vector__XXX
 SG_ BMS_ThermistorVoltages_tm5 m0 : 48|9@1+ (0.01,0) [0|5.12] "V" Vector__XXX
 SG_ BMS_ThermistorVoltages_tm6 m1 : 3|9@1+ (0.01,0) [0|5.12] "V" Vector__XXX
 SG_ BMS_ThermistorVoltages_tm7 m1 : 12|9@1+ (0.01,0) [0|5.12] "V" Vector__XXX
 SG_ BMS_ThermistorVoltages_tm8 m1 : 21|9@1+ (0.01,0) [0|5.12] "V" Vector__XXX
 SG_ BMS_ThermistorVoltages_tm9 m1 : 30|9@1+ (0.01,0) [0|5.12] "V" Vector__XXX
 SG_ BMS_ThermistorVoltages_tm10 m1 : 39|9@1+ (0.01,0) [0|5.12] "V" Vector__XXX
 SG_ BMS_ThermistorVoltages_tm11 m1 : 48|9@1+ (0.01,0) [0|5.12] "V" Vector__XXX
 SG_ BMS_ThermistorVoltages_tm12 m2 : 3|9@1+ (0.01,0) [0|5.12] "V" Vector__XXX
 SG_ BMS_ThermistorVoltages_tm13 m2 : 12|9@1+ (0.01,0) [0|5.12] "V" Vector__XXX
 SG_ BMS_ThermistorVoltages_tm14 m2 : 21|9@1+ (0.01,0) [0|5.12] "V" Vector__XXX
 SG_ BMS_ThermistorVoltages_tm15 m2 : 30|9@1+ (0.01,0) [0|5.12] "V" Vector__XXX
 SG_ BMS_ThermistorVoltages_tm16 m2 : 39|9@1+ (0.01,0) [0|5.12] "V" Vector__XXX
 SG_ BMS_ThermistorVoltages_tm17 m2 : 48|9@1+ (0.01,0) [0|5.12] "V" Vector__XXX
 SG_ BMS_ThermistorVoltages_tm18 m3 : 3|9@1+ (0.01,0) [0|5.12] "V" Vector__XXX
 SG_ BMS_ThermistorVoltages_tm19 m3 : 12|9@1+ (0.01,0) [0|5.12] "V" Vector__XXX
 SG_ BMS_ThermistorVoltages_tm20 m3 : 21|9@1+ (0.01,0) [0|5.12] "V" Vector__XXX
 SG_ BMS_ThermistorVoltages_tm21 m3 : 30|9@1+ (0.01,0) [0|5.12] "V" Vector__XXX
 SG_ BMS_ThermistorVoltages_tm22 m3 : 39|9@1+ (0.01,0) [0|5.12] "V" Vector__XXX
 SG_ BMS_ThermistorVoltages_tm23 m3 : 48|9@1+ (0.01,0) [0|5.12] "V" Vector__XXX
 SG_ BMS_ThermistorVoltages_tm24 m4 : 3|9@1+ (0.01,0) [0|5.12] "V" Vector__XXX
 SG_ BMS_ThermistorVoltages_tm25 m4 : 12|9@1+ (0.01,0) [0|5.12] "V" Vector__XXX
 SG_ BMS_ThermistorVoltages_tm26 m4 : 21|9@1+ (0.01,0) [0|5.12] "V" Vector__XXX
 SG_ BMS_ThermistorVoltages_tm27 m4 : 30|9@1+ (0.01,0) [0|5.12] "V" Vector__XXX
 SG_ BMS_ThermistorVoltages_tm28 m4 : 39|9@1+ (0.01,0) [0|5.12] "V" Vector__XXX
 SG_ BMS_ThermistorVoltages_tm29 m4 : 48|9@1+ (0.01,0) [0|5.12] "V" Vector__XXX
 SG_ BMS_ThermistorVoltages_tm30 m5 : 3|9@1+ (0.01,0) [0|5.12] "V" Vector__XXX
 SG_ BMS_ThermistorVoltages_tm31 m5 : 12|9@1+ (0.01,0) [0|5.12] "V" Vector__XXX
 SG_ BMS_ThermistorVoltages_tm32 m5 : 21|9@1+ (0.01,0) [0|5.12] "V" Vector__XXX
 SG_ BMS_ThermistorVoltages_tm33 m5 : 30|9@1+ (0.01,0) [0|5.12] "V" Vector__XXX
 SG_ BMS_ThermistorVoltages_tm34 m5 : 39|9@1+ (0.01,0) [0|5.12] "V" Vector__XXX
 SG_ BMS_ThermistorVoltages_tm35 m5 : 48|9@1+ (0.01,0) [0|5.12] "V" Vector__XXX
 SG_ BMS_ThermistorVoltages_tm36 m6 : 3|9@1+ (0.01,0) [0|5.12] "V" Vector__XXX
 SG_ BMS_ThermistorVoltages_tm37 m6 : 12|9@1+ (0.01,0) [0|5.12] "V" Vector__XXX
 SG_ BMS_ThermistorVoltages_tm38 m6 : 21|9@1+ (0.01,0) [0|5.12] "V" Vector__XXX
 SG_ BMS_ThermistorVoltages_tm39 m6 : 30|9@1+ (0.01,0) [0|5.12] "V" Vector__XXX

BO_ 704 BMS_Temperatures: 8 BMS
 SG_ BMS_Temperatures_mux M : 0|3@1+ (1,0) [0|5] "" Vector__XXX
 SG_ BMS_Temperatures_0 m0 : 3|8@1- (1,0) [-128|127] "C" Vector__XXX
 SG_ BMS_Temperatures_1 m0 : 11|8@1- (1,0) [-128|127] "C" Vector__XXX
 SG_ BMS_Temperatures_2 m0 : 19|8@1- (1,0) [-128|127] "C" Vector__XXX
 SG_ BMS_Temperatures_3 m0 : 27|8@1- (1,0) [-128|127] "C" Vector__XXX
 SG_ BMS_Temperatures_4 m0 : 35|8@1- (1,0) [-128|127] "C" Vector__XXX
 SG_ BMS_Temperatures_5 m0 : 43|8@1- (1,0) [-128|127] "C" Vector__XXX
 SG_ BMS_Temperatures_6 m0 : 51|8@1- (1,0) [-128|127] "C" Vector__XXX
 SG_ BMS_Temperatures_7 m1 : 3|8@1- (1,0) [-128|127] "C" Vector__XXX
 SG_ BMS_Temperatures_8 m1 : 11|8@1- (1,0) [-128|127] "C" Vector__XXX
 SG_ BMS_Temperatures_9 m1 : 19|8@1- (1,0) [-128|127] "C" Vector__XXX
 SG_ BMS_Temperatures_10 m1 : 27|8@1- (1,0) [-128|127] "C" Vector__XXX
 SG_ BMS_Temperatures_11 m1 : 35|8@1- (1,0) [-128|127] "C" Vector__XXX
 SG_ BMS_Temperatures_12 m1 : 43|8@1- (1,0) [-128|127] "C" Vector__XXX
 SG_ BMS_Temperatures_13 m1 : 51|8@1- (1,0) [-128|127] "C" Vector__XXX
 SG_ BMS_Temperatures_14 m2 : 3|8@1- (1,0) [-128|127] "C" Vector__XXX
 SG_ BMS_Temperatures_15 m2 : 11|8@1- (1,0) [-128|127] "C" Vector__XXX
 SG_ BMS_Temperatures_16 m2 : 19|8@1- (1,0) [-128|127] "C" Vector__XXX
 SG_ BMS_Temperatures_17 m2 : 27|8@1- (1,0) [-128|127] "C" Vector__XXX
 SG_ BMS_Temperatures_18 m2 : 35|8@1- (1,0) [-128|127] "C" Vector__XXX
 SG_ BMS_Temperatures_19 m2 : 43|8@1- (1,0) [-128|127] "C" Vector__XXX
 SG_ BMS_Temperatures_20 m2 : 51|8@1- (1,0) [-128|127] "C" Vector__XXX
 SG_ BMS_Temperatures_21 m3 : 3|8@1- (1,0) [-128|127] "C" Vector__XXX
 SG_ BMS_Temperatures_22 m3 : 11|8@1- (1,0) [-128|127] "C" Vector__XXX
 SG_ BMS_Temperatures_23 m3 : 19|8@1- (1,0) [-128|127] "C" Vector__XXX
 SG_ BMS_Temperatures_24 m3 : 27|8@1- (1,0) [-128|127] "C" Vector__XXX
 SG_ BMS_Temperatures_25 m3 : 35|8@1- (1,0) [-128|127] "C" Vector__XXX
 SG_ BMS_Temperatures_26 m3 : 43|8@1- (1,0) [-128|127] "C" Vector__XXX
 SG_ BMS_Temperatures_27 m3 : 51|8@1- (1,0) [-128|127] "C" Vector__XXX
 SG_ BMS_Temperatures_28 m4 : 3|8@1- (1,0) [-128|127] "C" Vector__XXX
 SG_ BMS_Temperatures_29 m4 : 11|8@1- (1,0) [-128|127] "C" Vector__XXX
 SG_ BMS_Temperatures_30 m4 : 19|8@1- (1,0) [-128|127] "C" Vector__XXX
 SG_ BMS_Temperatures_31 m4 : 27|8@1- (1,0) [-128|127] "C" Vector__XXX
 SG_ BMS_Temperatures_32 m4 : 35|8@1- (1,0) [-128|127] "C" Vector__XXX
 SG_ BMS_Temperatures_33 m4 : 43|8@1- (1,0) [-128|127] "C" Vector__XXX
 SG_ BMS_Temperatures_34 m4 : 51|8@1- (1,0) [-128|127] "C" Vector__XXX
 SG_ BMS_Temperatures_35 m5 : 3|8@1- (1,0) [-128|127] "C" Vector__XXX
 SG_ BMS_Temperatures_36 m5 : 11|8@1- (1,0) [-128|127] "C" Vector__XXX
 SG_ BMS_Temperatures_37 m5 : 19|8@1- (1,0) [-128|127] "C" Vector__XXX
 SG_ BMS_Temperatures_38 m5 : 27|8@1- (1,0) [-128|127] "C" Vector__XXX
 SG_ BMS_Temperatures_39 m5 : 35|8@1- (1,0) [-128|127] "C" Vector__XXX

BO_ 800 BMS_DrainStatusA: 8 BMS
 SG_ BMS_DrainStatusA_Cell0 : 0|1@1+ (1,0) [0|1] "" Vector__XXX
 SG_ BMS_DrainStatusA_Cell1 : 1|1@1+ (1,0) [0|1] "" Vector__XXX
 SG_ BMS_DrainStatusA_Cell2 : 2|1@1+ (1,0) [0|1] "" Vector__XXX
 SG_ BMS_DrainStatusA_Cell3 : 3|1@1+ (1,0) [0|1] "" Vector__XXX
 SG_ BMS_DrainStatusA_Cell4 : 4|1@1+ (1,0) [0|1] "" Vector__XXX
 SG_ BMS_DrainStatusA_Cell5 : 5|1@1+ (1,0) [0|1] "" Vector__XXX
 SG_ BMS_DrainStatusA_Cell6 : 6|1@1+ (1,0) [0|1] "" Vector__XXX
 SG_ BMS_DrainStatusA_Cell7 : 7|1@1+ (1,0) [0|1] "" Vector__XXX
 SG_ BMS_DrainStatusA_Cell8 : 8|1@1+ (1,0) [0|1] "" Vector__XXX
 SG_ BMS_DrainStatusA_Cell9 : 9|1@1+ (1,0) [0|1] "" Vector__XXX
 SG_ BMS_DrainStatusA_Cell10 : 10|1@1+ (1,0) [0|1] "" Vector__XXX
 SG_ BMS_DrainStatusA_Cell11 : 11|1@1+ (1,0) [0|1] "" Vector__XXX
 SG_ BMS_DrainStatusA_Cell12 : 12|1@1+ (1,0) [0|1] "" Vector__XXX
 SG_ BMS_DrainStatusA_Cell13 : 13|1@1+ (1,0) [0|1] "" Vector__XXX
 SG_ BMS_DrainStatusA_Cell14 : 14|1@1+ (1,0) [0|1] "" Vector__XXX
 SG_ BMS_DrainStatusA_Cell15 : 15|1@1+ (1,0) [0|1] "" Vector__XXX
 SG_ BMS_DrainStatusA_Cell16 : 16|1@1+ (1,0) [0|1] "" Vector__XXX
 SG_ BMS_DrainStatusA_Cell17 : 17|1@1+ (1,0) [0|1] "" Vector__XXX
 SG_ BMS_DrainStatusA_Cell18 : 18|1@1+ (1,0) [0|1] "" Vector__XXX
 SG_ BMS_DrainStatusA_Cell19 : 19|1@1+ (1,0) [0|1] "" Vector__XXX
 SG_ BMS_DrainStatusA_Cell20 : 20|1@1+ (1,0) [0|1] "" Vector__XXX
 SG_ BMS_DrainStatusA_Cell21 : 21|1@1+ (1,0) [0|1] "" Vector__XXX
 SG_ BMS_DrainStatusA_Cell22 : 22|1@1+ (1,0) [0|1] "" Vector__XXX
 SG_ BMS_DrainStatusA_Cell23 : 23|1@1+ (1,0) [0|1] "" Vector__XXX
 SG_ BMS_DrainStatusA_Cell24 : 24|1@1+ (1,0) [0|1] "" Vector__XXX
 SG_ BMS_DrainStatusA_Cell25 : 25|1@1+ (1,0) [0|1] "" Vector__XXX
 SG_ BMS_DrainStatusA_Cell26 : 26|1@1+ (1,0) [0|1] "" Vector__XXX
 SG_ BMS_DrainStatusA_Cell27 : 27|1@1+ (1,0) [0|1] "" Vector__XXX
 SG_ BMS_DrainStatusA_Cell28 : 28|1@1+ (1,0) [0|1] "" Vector__XXX
 SG_ BMS_DrainStatusA_Cell29 : 29|1@1+ (1,0) [0|1] "" Vector__XXX
 SG_ BMS_DrainStatusA_Cell30 : 30|1@1+ (1,0) [0|1] "" Vector__XXX
 SG_ BMS_DrainStatusA_Cell31 : 31|1@1+ (1,0) [0|1] "" Vector__XXX
 SG_ BMS_DrainStatusA_Cell32 : 32|1@1+ (1,0) [0|1] "" Vector__XXX
 SG_ BMS_DrainStatusA_Cell33 : 33|1@1+ (1,0) [0|1] "" Vector__XXX
 SG_ BMS_DrainStatusA_Cell34 : 34|1@1+ (1,0) [0|1] "" Vector__XXX
 SG_ BMS_DrainStatusA_Cell35 : 35|1@1+ (1,0) [0|1] "" Vector__XXX
 SG_ BMS_DrainStatusA_Cell36 : 36|1@1+ (1,0) [0|1] "" Vector__XXX
 SG_ BMS_DrainStatusA_Cell37 : 37|1@1+ (1,0) [0|1] "" Vector__XXX
 SG_ BMS_DrainStatusA_Cell38 : 38|1@1+ (1,0) [0|1] "" Vector__XXX
 SG_ BMS_DrainStatusA_Cell39 : 39|1@1+ (1,0) [0|1] "" Vector__XXX
 SG_ BMS_DrainStatusA_Cell40 : 40|1@1+ (1,0) [0|1] "" Vector__XXX
 SG_ BMS_DrainStatusA_Cell41 : 41|1@1+ (1,0) [0|1] "" Vector__XXX
 SG_ BMS_DrainStatusA_Cell42 : 42|1@1+ (1,0) [0|1] "" Vector__XXX
 SG_ BMS_DrainStatusA_Cell43 : 43|1@1+ (1,0) [0|1] "" Vector__XXX
 SG_ BMS_DrainStatusA_Cell44 : 44|1@1+ (1,0) [0|1] "" Vector__XXX
 SG_ BMS_DrainStatusA_Cell45 : 45|1@1+ (1,0) [0|1] "" Vector__XXX
 SG_ BMS_DrainStatusA_Cell46 : 46|1@1+ (1,0) [0|1] "" Vector__XXX
 SG_ BMS_DrainStatusA_Cell47 : 47|1@1+ (1,0) [0|1] "" Vector__XXX
 SG_ BMS_DrainStatusA_Cell48 : 48|1@1+ (1,0) [0|1] "" Vector__XXX
 SG_ BMS_DrainStatusA_Cell49 : 49|1@1+ (1,0) [0|1] "" Vector__XXX
 SG_ BMS_DrainStatusA_Cell50 : 50|1@1+ (1,0) [0|1] "" Vector__XXX
 SG_ BMS_DrainStatusA_Cell51 : 51|1@1+ (1,0) [0|1] "" Vector__XXX
 SG_ BMS_DrainStatusA_Cell52 : 52|1@1+ (1,0) [0|1] "" Vector__XXX
 SG_ BMS_DrainStatusA_Cell53 : 53|1@1+ (1,0) [0|1] "" Vector__XXX
 SG_ BMS_DrainStatusA_Cell54 : 54|1@1+ (1,0) [0|1] "" Vector__XXX
 SG_ BMS_DrainStatusA_Cell55 : 55|1@1+ (1,0) [0|1] "" Vector__XXX
 SG_ BMS_DrainStatusA_Cell56 : 56|1@1+ (1,0) [0|1] "" Vector__XXX
 SG_ BMS_DrainStatusA_Cell57 : 57|1@1+ (1,0) [0|1] "" Vector__XXX
 SG_ BMS_DrainStatusA_Cell58 : 58|1@1+ (1,0) [0|1] "" Vector__XXX
 SG_ BMS_DrainStatusA_Cell59 : 59|1@1+ (1,0) [0|1] "" Vector__XXX
 SG_ BMS_DrainStatusA_Cell60 : 60|1@1+ (1,0) [0|1] "" Vector__XXX
 SG_ BMS_DrainStatusA_Cell61 : 61|1@1+ (1,0) [0|1] "" Vector__XXX
 SG_ BMS_DrainStatusA_Cell62 : 62|1@1+ (1,0) [0|1] "" Vector__XXX
 SG_ BMS_DrainStatusA_Cell63 : 63|1@1+ (1,0) [0|1] "" Vector__XXX

BO_ 801 BMS_DrainStatusB: 8 BMS
 SG_ BMS_DrainStatusB_Cell64 : 0|1@1+ (1,0) [0|1] "" Vector__XXX
 SG_ BMS_DrainStatusB_Cell65 : 1|1@1+ (1,0) [0|1] "" Vector__XXX
 SG_ BMS_DrainStatusB_Cell66 : 2|1@1+ (1,0) [0|1] "" Vector__XXX
 SG_ BMS_DrainStatusB_Cell67 : 3|1@1+ (1,0) [0|1] "" Vector__XXX
 SG_ BMS_DrainStatusB_Cell68 : 4|1@1+ (1,0) [0|1] "" Vector__XXX
 SG_ BMS_DrainStatusB_Cell69 : 5|1@1+ (1,0) [0|1] "" Vector__XXX
 SG_ BMS_DrainStatusB_Cell70 : 6|1@1+ (1,0) [0|1] "" Vector__XXX
 SG_ BMS_DrainStatusB_Cell71 : 7|1@1+ (1,0) [0|1] "" Vector__XXX
 SG_ BMS_DrainStatusB_Cell72 : 8|1@1+ (1,0) [0|1] "" Vector__XXX
 SG_ BMS_DrainStatusB_Cell73 : 9|1@1+ (1,0) [0|1] "" Vector__XXX
 SG_ BMS_DrainStatusB_Cell74 : 10|1@1+ (1,0) [0|1] "" Vector__XXX
 SG_ BMS_DrainStatusB_Cell75 : 11|1@1+ (1,0) [0|1] "" Vector__XXX
 SG_ BMS_DrainStatusB_Cell76 : 12|1@1+ (1,0) [0|1] "" Vector__XXX
 SG_ BMS_DrainStatusB_Cell77 : 13|1@1+ (1,0) [0|1] "" Vector__XXX
 SG_ BMS_DrainStatusB_Cell78 : 14|1@1+ (1,0) [0|1] "" Vector__XXX
 SG_ BMS_DrainStatusB_Cell79 : 15|1@1+ (1,0) [0|1] "" Vector__XXX
 SG_ BMS_DrainStatusB_Cell80 : 16|1@1+ (1,0) [0|1] "" Vector__XXX
 SG_ BMS_DrainStatusB_Cell81 : 17|1@1+ (1,0) [0|1] "" Vector__XXX
 SG_ BMS_DrainStatusB_Cell82 : 18|1@1+ (1,0) [0|1] "" Vector__XXX
 SG_ BMS_DrainStatusB_Cell83 : 19|1@1+ (1,0) [0|1] "" Vector__XXX
 SG_ BMS_DrainStatusB_Cell84 : 20|1@1+ (1,0) [0|1] "" Vector__XXX
 SG_ BMS_DrainStatusB_Cell85 : 21|1@1+ (1,0) [0|1] "" Vector__XXX
 SG_ BMS_DrainStatusB_Cell86 : 22|1@1+ (1,0) [0|1] "" Vector__XXX
 SG_ BMS_DrainStatusB_Cell87 : 23|1@1+ (1,0) [0|1] "" Vector__XXX
 SG_ BMS_DrainStatusB_Cell88 : 24|1@1+ (1,0) [0|1] "" Vector__XXX
 SG_ BMS_DrainStatusB_Cell89 : 25|1@1+ (1,0) [0|1] "" Vector__XXX

BO_ 900 BMS_Current: 8 BMS
 SG_ BMS_InstCurrentFilt : 0|32@1- (0.001,0) [-100|250] "A"  DASH

BO_ 950 BMS_HardFaultIndicator: 8 BMS
 SG_ BMS_HardFaultIndicator_task : 0|4@1+ (1,0) [0|15] "" Vector__XXX

BO_ 951 BMS_Ref: 8 BMS
 SG_ BMS_Ref_mux M : 0|1@1+ (1,0) [0|1] "" Vector__XXX
 SG_ BMS_Ref_ref0 m0 : 1|9@1+ (0.01,0) [0|5.12] "V" Vector__XXX
 SG_ BMS_Ref_ref1 m0 : 10|9@1+ (0.01,0) [0|5.12] "V" Vector__XXX
 SG_ BMS_Ref_ref2 m0 : 19|9@1+ (0.01,0) [0|5.12] "V" Vector__XXX
 SG_ BMS_Ref_ref3 m0 : 28|9@1+ (0.01,0) [0|5.12] "V" Vector__XXX
 SG_ BMS_Ref_ref4 m0 : 37|9@1+ (0.01,0) [0|5.12] "V" Vector__XXX
 SG_ BMS_Ref_ref5 m0 : 46|9@1+ (0.01,0) [0|5.12] "V" Vector__XXX
 SG_ BMS_Ref_ref6 m1 : 1|9@1+ (0.01,0) [0|5.12] "V" Vector__XXX
 SG_ BMS_Ref_ref7 m1 : 10|9@1+ (0.01,0) [0|5.12] "V" Vector__XXX
 SG_ BMS_Ref_ref8 m1 : 19|9@1+ (0.01,0) [0|5.12] "V" Vector__XXX
 SG_ BMS_Ref_ref9 m1 : 28|9@1+ (0.01,0) [0|5.12] "V" Vector__XXX
 SG_ BMS_Ref_ref10 m1 : 37|9@1+ (0.01,0) [0|5.12] "V" Vector__XXX
 SG_ BMS_Ref_ref11 m1 : 46|9@1+ (0.01,0) [0|5.12] "V" Vector__XXX

BO_ 901 BMS_LimpMode: 8 BMS
 SG_ BMS_LimpMode_VoltageLimpLevel : 0|2@1+ (1,0) [0|4] "" Vector__XXX
 SG_ BMS_LimpMode_TempLimpLevel : 2|2@1+ (1,0) [0|4] "" Vector__XXX
 SG_ BMS_LimpMode_VoltageCurrentLimit : 4|9@1- (1,0) [-100|500] "A" Vector__XXX
 SG_ BMS_LimpMode_TempCurrentLimit : 13|9@1- (1,0) [-100|500] "A" Vector__XXX

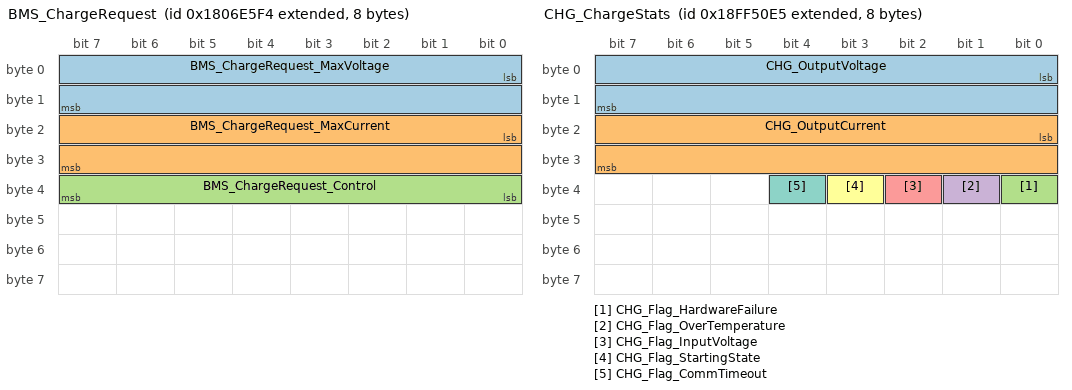
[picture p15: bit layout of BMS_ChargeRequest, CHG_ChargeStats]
BO_ 2550588916 BMS_ChargeRequest: 8 BMS
 SG_ BMS_ChargeRequest_MaxVoltage : 0|16@1+ (0.1,0) [0|6553.5] "V"  CHG
 SG_ BMS_ChargeRequest_MaxCurrent : 16|16@1+ (0.1,0) [0|6553.5] "A"  CHG
 SG_ BMS_ChargeRequest_Control : 32|8@1+ (1,0) [0|1] ""  CHG

BO_ 2566869221 CHG_ChargeStats: 8 CHG
 SG_ CHG_OutputVoltage : 0|16@1+ (0.1,0) [0|6553.5] "V" Vector__XXX
 SG_ CHG_OutputCurrent : 16|16@1+ (0.1,0) [0|6553.5] "A" Vector__XXX
 SG_ CHG_Flag_HardwareFailure : 32|1@1+ (1,0) [0|1] "" Vector__XXX
 SG_ CHG_Flag_OverTemperature : 33|1@1+ (1,0) [0|1] "" Vector__XXX
 SG_ CHG_Flag_InputVoltage : 34|1@1+ (1,0) [0|1] "" Vector__XXX
 SG_ CHG_Flag_StartingState : 35|1@1+ (1,0) [0|1] "" Vector__XXX
 SG_ CHG_Flag_CommTimeout : 36|1@1+ (1,0) [0|1] "" Vector__XXX

CM_ BU_ C70 "Bosch C70 Data Logger";
CM_ BU_ VC "Vehicle Controller";
CM_ BU_ MCU "Motor Control Unit";
CM_ BU_ BMS "Battery Management System";
CM_ BU_ CHG "Charge Cart";
CM_ BU_ DASH "Dashboard Display";
CM_ BO_ 1790 "Wheel speeds, relayed by C70";
CM_ BO_ 1791 "Brake Pressures, relayed by C70";
BA_DEF_ SG_  "SystemSignalLongSymbol" STRING ;
BA_DEF_DEF_  "SystemSignalLongSymbol" "";
BA_ "SystemSignalLongSymbol" SG_ 305 VC_ShutdownStatus_BSPD_signal_lo "VC_ShutdownStatus_BSPD_signal_lost";
BA_ "SystemSignalLongSymbol" SG_ 311 VC_FaultVector_BRAKE_SENSOR_IRRA "VC_FaultVector_BRAKE_SENSOR_IRRATIONAL";
BA_ "SystemSignalLongSymbol" SG_ 311 VC_FaultVector_ACCELERATOR_SENSO "VC_FaultVector_ACCELERATOR_SENSOR_IRRATIONAL";
BA_ "SystemSignalLongSymbol" SG_ 311 VC_FaultVector_APPS_SENSOR_DISAG "VC_FaultVector_APPS_SENSOR_DISAGREEMENT";
BA_ "SystemSignalLongSymbol" SG_ 469 D1_HV_Input_Current_Sensor_Valid "D1_HV_Input_Current_Sensor_Validity";
BA_ "SystemSignalLongSymbol" SG_ 700 BMS_FaultVector_SLAVE_COMM_DRAIN "BMS_FaultVector_SLAVE_COMM_DRAIN_REQUEST";
BA_ "SystemSignalLongSymbol" SG_ 700 BMS_FaultVector_CURRENT_SENSOR_C "BMS_FaultVector_CURRENT_SENSOR_COMM";
BA_ "SystemSignalLongSymbol" SG_ 700 BMS_FaultVector_CELL_VOLTAGE_IRR "BMS_FaultVector_CELL_VOLTAGE_IRRATIONAL";
BA_ "SystemSignalLongSymbol" SG_ 700 BMS_FaultVector_CELL_VOLTAGE_DIF "BMS_FaultVector_CELL_VOLTAGE_DIFF";
BA_ "SystemSignalLongSymbol" SG_ 700 BMS_FaultVector_TEMPERATURE_IRRA "BMS_FaultVector_TEMPERATURE_IRRATIONAL";
BA_ "SystemSignalLongSymbol" SG_ 701 BMS_FaultAlert_cell_comm_slave_b "BMS_FaultAlert_cell_comm_slave_board_num";
BA_ "SystemSignalLongSymbol" SG_ 701 BMS_FaultAlert_temp_comm_slave_b "BMS_FaultAlert_temp_comm_slave_board_num";
BA_ "SystemSignalLongSymbol" SG_ 701 BMS_FaultAlert_drain_comm_slave_ "BMS_FaultAlert_drain_comm_slave_board_num";
BA_ "SystemSignalLongSymbol" SG_ 701 BMS_FaultAlert_irrational_voltag "BMS_FaultAlert_irrational_voltage";
BA_ "SystemSignalLongSymbol" SG_ 701 BMS_FaultAlert_lowest_cell_volta "BMS_FaultAlert_lowest_cell_voltage";
BA_ "SystemSignalLongSymbol" SG_ 701 BMS_FaultAlert_irrational_temper "BMS_FaultAlert_irrational_temperature";
VAL_ 301 VC_Status_VehicleState 0 "VehicleState_NOT_READY" 1 "VehicleState_STARTUP" 2 "VehicleState_READY_TO_DRIVE" 3 "VehicleState_FAULTED" ;
VAL_ 315 VC_HardFaultIndicator_task 0 "unknown" 1 "task_100Hz" ;
VAL_ 192 Direction_Command 0 "CW" 1 "CCW" ;
VAL_ 192 Inverter_Discharge 0 "Discharge Disable" 1 "Discharge Enable (if EEPROM parameter is set)" ;
VAL_ 170 D2_Inverter_State 0 "Power up" 1 "Stop" 2 "Open Loop" 3 "Closed Loop" 4 "Internal State" 5 "Internal State" 6 "Internal State" 7 "Internal State" 8 "Idle Run" 9 "Idle Stop" 10 "Internal State" 11 "Intern State" 12 "Internal State" ;
VAL_ 170 D1_VSM_State 0 "VSM Start State" 1 "Pre-Charge Init state" 2 "pre-charge active state" 3 "pre-charge complete state" 4 "VSM wait state" 5 "VSM ready state" 6 "Motor Running State" 7 "blink fault code state" 14 "Shutdown state for Key Switch Mode 1" 15 "Reset the inverter" ;
VAL_ 600 BMS_Status_ChargeState 0 "ChargeState_DISCONNECTED" 1 "ChargeState_CONNECTED_COMPLETE" 2 "ChargeState_CONNECTED_BALANCING" 3 "ChargeState_CONNECTED_CHARGING" 4 "ChargeState_CONNECTED_BALANCE_SENSING" ;
VAL_ 701 BMS_FaultAlert_code 0 "FaultCode_SLAVE_COMM_CELLS" 1 "FaultCode_SLAVE_COMM_TEMPS" 2 "FaultCode_SLAVE_COMM_DRAIN_REQUEST" 3 "FaultCode_CURRENT_SENSOR_COMM" 4 "FaultCode_OVER_CURRENT" 5 "FaultCode_CELL_VOLTAGE_IRRATIONAL" 6 "FaultCode_CELL_VOLTAGE_DIFF" 7 "Faultcode_OUT_OF_JUICE" 8 "FaultCode_TEMPERATURE_IRRATIONAL" 9 "FaultCode_OVER_TEMP" 10 "FaultCode_DRAIN_FAILURE" ;
VAL_ 950 BMS_HardFaultIndicator_task 0 "unknown" 1 "task_100Hz" 2 "task_1kHz" 3 "can_main_rx_task" 4 "can_sensor_rx_task" 5 "can_tx_task" ;
VAL_ 901 BMS_LimpMode_VoltageLimpLevel 0 "LimpModeLevel_NO_LIMP" 1 "LimpModeLevel_LEVEL_1" 2 "LimpModeLevel_LEVEL_2" 3 "LimpModeLevel_LEVEL_3" ;
VAL_ 901 BMS_LimpMode_TempLimpLevel 0 "LimpModeLevel_NO_LIMP" 1 "LimpModeLevel_LEVEL_1" 2 "LimpModeLevel_LEVEL_2" 3 "LimpModeLevel_LEVEL_3" ;
